AUTOSAR XML (schema 314)
package /ComponentType
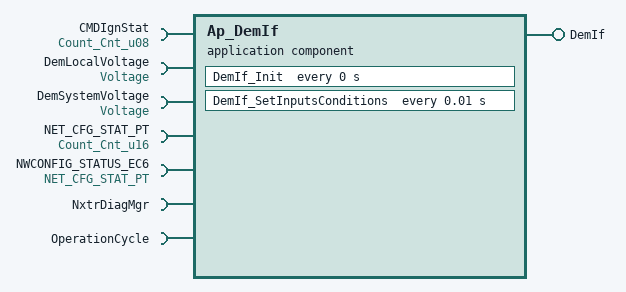
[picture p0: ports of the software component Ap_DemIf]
  application software component type Ap_DemIf
    provide port DemIf: provided-interface=DemIf
      provided-com-specs:
        operation=DemShutdown, queue-length=1
        operation=RestartDem, queue-length=1
        operation=SetEventStatus, queue-length=1
        operation=SetOperationCycleState, queue-length=1
    7 x require port:
      CMDIgnStat: unqueued-receiver-com-spec{data-element=Cnt_u08, init-value=D_ZERO_CNT_U8}, required-interface=Count_Cnt_u08
      DemLocalVoltage: unqueued-receiver-com-spec{data-element=Volt_f32, init-value=D_VECUMIN_VOLTS_F32}, required-interface=Voltage
      DemSystemVoltage: unqueued-receiver-com-spec{data-element=Volt_f32, init-value=D_VECUMIN_VOLTS_F32}, required-interface=Voltage
      NET_CFG_STAT_PT: unqueued-receiver-com-spec{data-element=Cnt_u16, init-value=D_ZERO_CNT_U16}, required-interface=Count_Cnt_u16
      NWCONFIG_STATUS_EC6: unqueued-receiver-com-spec{data-element=DE_NET_CFG_STAT_PT, init-value=Init_NET_CFG_STAT_PT}, required-interface=NET_CFG_STAT_PT
      NxtrDiagMgr: required-com-specs=[GetNTCActive, GetNTCFailed, GetNTCStatus, SetNTCStatus], required-interface=NxtrDiagMgr
      OperationCycle: client-com-spec=SetOperationCycleState, required-interface=OperationCycle
  internal behavior Ap_DemIf_InternalBehavior: component=Ap_DemIf
    timing event DemIf_InitEvent: start-on-event=DemIf_Init, period=0
    operation invoked event OIT_DemIf_RestartDem_DemIf_RestartDem: start-on-event=DemIf_RestartDem, operation=DemIf.RestartDem
    operation invoked event OIT_DemIf_SetEventStatus_DemIf_SetEventStatus: start-on-event=DemIf_SetEventStatus, operation=DemIf.SetEventStatus
    timing event TMT_DemIf_SetInputsConditions: start-on-event=DemIf_SetInputsConditions, period=0.01
    operation invoked event OIT_DemIf_SetOperationCycleState_DemIf_SetOperationCycleState: start-on-event=DemIf_SetOperationCycleState, operation=DemIf.SetOperationCycleState
    operation invoked event OIT_DemIf_Shutdown_DemIf_DemShutdown: start-on-event=DemIf_Shutdown, operation=DemIf.DemShutdown
    port-api-options:
      enable-take-address=false, indirect-api=false, port=CMDIgnStat
      enable-take-address=false, indirect-api=false, port=DemIf
      enable-take-address=false, indirect-api=false, port=DemLocalVoltage
      enable-take-address=false, indirect-api=false, port=DemSystemVoltage
      enable-take-address=false, indirect-api=false, port=NET_CFG_STAT_PT
      enable-take-address=false, indirect-api=false, port=NWCONFIG_STATUS_EC6
      enable-take-address=false, indirect-api=false, port=NxtrDiagMgr
      enable-take-address=false, indirect-api=false, port=OperationCycle
    6 x runnable:
      DemIf_Init
      DemIf_RestartDem
      DemIf_SetEventStatus
        data receive point REC_CMDIgnStat_Cnt_u08: data-element=CMDIgnStat.Cnt_u08
        data receive point REC_NET_CFG_STAT_PT_Cnt_u16: data-element=NET_CFG_STAT_PT.Cnt_u16
        sync call SC_NxtrDiagMgr_GetNTCFailed: operation=NxtrDiagMgr.GetNTCFailed, timeout=0
      DemIf_SetInputsConditions
        4 x data read access:
          READ_DemLocalVoltage_Volt_f32: data-element=DemLocalVoltage.Volt_f32
          READ_DemSystemVoltage_Volt_f32: data-element=DemSystemVoltage.Volt_f32
          READ_NET_CFG_STAT_PT_Cnt_u16: data-element=NET_CFG_STAT_PT.Cnt_u16
          READ_NWCONFIG_STATUS_EC6_DE_NET_CFG_STAT_PT: data-element=NWCONFIG_STATUS_EC6.DE_NET_CFG_STAT_PT
        sync call SC_NxtrDiagMgr_GetNTCStatus: operation=NxtrDiagMgr.GetNTCStatus, timeout=0
      DemIf_SetOperationCycleState: can-be-invoked-concurrently=true
        sync call SC_OperationCycle_SetOperationCycleState: operation=OperationCycle.SetOperationCycleState, timeout=0
      DemIf_Shutdown
  swc implementation Ap_DemIf_Implementation: behavior=Ap_DemIf_InternalBehavior
    code-descriptors:
      code Code: type=SRC
